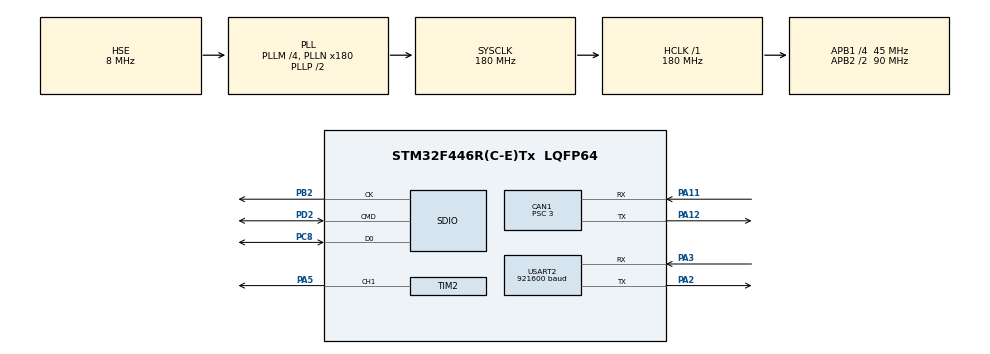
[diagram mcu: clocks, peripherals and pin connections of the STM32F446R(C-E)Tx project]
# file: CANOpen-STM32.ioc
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CAN1.BS1=CAN_BS1_12TQ
CAN1.BS2=CAN_BS2_3TQ
CAN1.CalculateTimeQuantum=66.66666666666666
CAN1.Prescaler=3
CAN1.SJW=CAN_SJW_2TQ
CAN1.TTCM=DISABLE
Dma.Request0=USART2_TX
Dma.USART2_TX.0.Direction=DMA_MEMORY_TO_PERIPH
Dma.USART2_TX.0.FIFOMode=DMA_FIFOMODE_DISABLE
Dma.USART2_TX.0.Instance=DMA1_Stream6
Dma.USART2_TX.0.MemDataAlignment=DMA_MDATAALIGN_BYTE
Dma.USART2_TX.0.MemInc=DMA_MINC_ENABLE
Dma.USART2_TX.0.Mode=DMA_NORMAL
Dma.USART2_TX.0.PeriphDataAlignment=DMA_PDATAALIGN_BYTE
Dma.USART2_TX.0.PeriphInc=DMA_PINC_DISABLE
Dma.USART2_TX.0.Priority=DMA_PRIORITY_LOW
FREERTOS.Tasks01=defaultTask,8,128,StartDefaultTask,Default,NULL,Static,defaultTaskBuffer,defaultTaskControlBlock;uartRxTask,9,256,StartUartRxTask,Default,NULL,Static,uartRxTaskBuffer,uartRxTaskControlBlock;canTxTask,24,256,StartCanTxTask,Default,NULL,Static,canTxTaskBuffer,canTxTaskControlBlock;canRxTask,24,256,StartCanRxTask,Default,NULL,Static,canRxTaskBuffer,canRxTaskControlBlock
Mcu.Family=STM32F4
Mcu.Name=STM32F446R(C-E)Tx
Mcu.Package=LQFP64
NVIC.DMA1_Stream6_IRQn=true\:5\:0\:false\:false\:true\:true\:false\:true
NVIC.PriorityGroup=NVIC_PRIORITYGROUP_4
NVIC.TIM2_IRQn=true\:5\:0\:false\:false\:true\:true\:true\:true
NVIC.TIM6_DAC_IRQn=true\:0\:0\:false\:false\:true\:false\:false\:true
NVIC.TIM7_IRQn=true\:5\:0\:false\:false\:true\:true\:true\:true
NVIC.TimeBase=TIM6_DAC_IRQn
NVIC.TimeBaseIP=TIM6
NVIC.USART2_IRQn=true\:5\:0\:false\:false\:true\:true\:true\:true
PA11.Mode=Master
PA11.Signal=CAN1_RX
PA12.Mode=Master
PA12.Signal=CAN1_TX
PA2.Mode=Asynchronous
PA2.Signal=USART2_TX
PA3.Mode=Asynchronous
PA3.Signal=USART2_RX
PA5.GPIO_Speed=GPIO_SPEED_FREQ_HIGH
PA5.Signal=S_TIM2_CH1_ETR
PB2.Mode=SD_1_bit
PB2.Signal=SDIO_CK
PC8.Mode=SD_1_bit
PC8.Signal=SDIO_D0
PD2.Mode=SD_1_bit
PD2.Signal=SDIO_CMD
PH0-OSC_IN.Mode=HSE-External-Oscillator
PH0-OSC_IN.Signal=RCC_OSC_IN
PH1-OSC_OUT.Mode=HSE-External-Oscillator
PH1-OSC_OUT.Signal=RCC_OSC_OUT
ProjectManager.HeapSize=0x200
ProjectManager.StackSize=0x400
ProjectManager.TargetToolchain=Makefile
RCC.AHBFreq_Value=180000000
RCC.APB1CLKDivider=RCC_HCLK_DIV4
RCC.APB1Freq_Value=45000000
RCC.APB1TimFreq_Value=90000000
RCC.APB2CLKDivider=RCC_HCLK_DIV2
RCC.APB2Freq_Value=90000000
RCC.APB2TimFreq_Value=180000000
RCC.CortexFreq_Value=180000000
RCC.HCLKFreq_Value=180000000
RCC.HSE_VALUE=8000000
RCC.PLLM=4
RCC.PLLN=180
RCC.PLLQ=8
RCC.PLLSourceVirtual=RCC_PLLSOURCE_HSE
RCC.SYSCLKFreq_VALUE=180000000
RCC.SYSCLKSource=RCC_SYSCLKSOURCE_PLLCLK
RCC.USBFreq_Value=45000000
RCC.VCOOutputFreq_Value=360000000
SH.S_TIM2_CH1_ETR.0=TIM2_CH1,PWM Generation1 CH1
TIM2.Channel-PWM\ Generation1\ CH1=TIM_CHANNEL_1
TIM2.Period=999
TIM2.Prescaler=89
TIM2.Pulse-PWM\ Generation1\ CH1=100
TIM7.AutoReloadPreload=TIM_AUTORELOAD_PRELOAD_DISABLE
TIM7.Period=9999
TIM7.Prescaler=8999
USART2.BaudRate=921600
USART2.VirtualMode=VM_ASYNC
VP_FREERTOS_VS_CMSIS_V2.Mode=CMSIS_V2
VP_SYS_VS_tim6.Mode=TIM6
VP_TIM2_VS_ClockSourceINT.Mode=Internal
VP_TIM7_VS_ClockSourceINT.Mode=Enable_Timer
board=custom

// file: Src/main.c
/* USER CODE BEGIN Header */
/**
  ******************************************************************************
  * @file           : main.c
  * @brief          : Main program body
  ******************************************************************************
  * @attention
  *
  * <h2><center>&copy; Copyright (c) 2020 STMicroelectronics.
  * All rights reserved.</center></h2>
  *
  * This software component is licensed by ST under Ultimate Liberty license
  * SLA0044, the "License"; You may not use this file except in compliance with
  * the License. You may obtain a copy of the License at:
  *                             www.st.com/SLA0044
  *
  ******************************************************************************
  */
/* USER CODE END Header */

#include "main.h"
#include "cmsis_os.h"
#include "can.h"
#include "dma.h"
#include "sdio.h"
#include "tim.h"
#include "usart.h"
#include "gpio.h"

void SystemClock_Config(void);
void MX_FREERTOS_Init(void);

int main(void)
{

  /* MCU Configuration--------------------------------------------------------*/

  /* Reset of all peripherals, Initializes the Flash interface and the Systick. */
  HAL_Init();

  /* Configure the system clock */
  SystemClock_Config();

  /* Initialize all configured peripherals */
  MX_GPIO_Init();
  MX_DMA_Init();
  MX_USART2_UART_Init();
  MX_TIM7_Init();
  MX_TIM2_Init();
  MX_CAN1_Init();
  MX_SDIO_SD_Init();
  /* USER CODE BEGIN 2 */
  USR_CAN1_Init();
  /* USER CODE END 2 */

  /* Call init function for freertos objects (in freertos.c) */
  MX_FREERTOS_Init();

  /* Start scheduler */
  osKernelStart();

  /* We should never get here as control is now taken by the scheduler */

  /* Infinite loop */
  while (1)
  {

  }
}

void SystemClock_Config(void)
{
  RCC_OscInitTypeDef RCC_OscInitStruct = {0};
  RCC_ClkInitTypeDef RCC_ClkInitStruct = {0};
  RCC_PeriphCLKInitTypeDef PeriphClkInitStruct = {0};

  /** Configure the main internal regulator output voltage
  */
  __HAL_RCC_PWR_CLK_ENABLE();
  __HAL_PWR_VOLTAGESCALING_CONFIG(PWR_REGULATOR_VOLTAGE_SCALE1);
  /** Initializes the CPU, AHB and APB busses clocks
  */
  RCC_OscInitStruct.OscillatorType = RCC_OSCILLATORTYPE_HSE;
  RCC_OscInitStruct.HSEState = RCC_HSE_ON;
  RCC_OscInitStruct.PLL.PLLState = RCC_PLL_ON;
  RCC_OscInitStruct.PLL.PLLSource = RCC_PLLSOURCE_HSE;
  RCC_OscInitStruct.PLL.PLLM = 4;
  RCC_OscInitStruct.PLL.PLLN = 180;
  RCC_OscInitStruct.PLL.PLLP = RCC_PLLP_DIV2;
  RCC_OscInitStruct.PLL.PLLQ = 8;
  RCC_OscInitStruct.PLL.PLLR = 2;
  if (HAL_RCC_OscConfig(&RCC_OscInitStruct) != HAL_OK)
  {
    Error_Handler();
  }
  /** Activate the Over-Drive mode
  */
  if (HAL_PWREx_EnableOverDrive() != HAL_OK)
  {
    Error_Handler();
  }
  /** Initializes the CPU, AHB and APB busses clocks
  */
  RCC_ClkInitStruct.ClockType = RCC_CLOCKTYPE_HCLK|RCC_CLOCKTYPE_SYSCLK
                              |RCC_CLOCKTYPE_PCLK1|RCC_CLOCKTYPE_PCLK2;
  RCC_ClkInitStruct.SYSCLKSource = RCC_SYSCLKSOURCE_PLLCLK;
  RCC_ClkInitStruct.AHBCLKDivider = RCC_SYSCLK_DIV1;
  RCC_ClkInitStruct.APB1CLKDivider = RCC_HCLK_DIV4;
  RCC_ClkInitStruct.APB2CLKDivider = RCC_HCLK_DIV2;

  if (HAL_RCC_ClockConfig(&RCC_ClkInitStruct, FLASH_LATENCY_5) != HAL_OK)
  {
    Error_Handler();
  }
  PeriphClkInitStruct.PeriphClockSelection = RCC_PERIPHCLK_SDIO|RCC_PERIPHCLK_CLK48;
  PeriphClkInitStruct.Clk48ClockSelection = RCC_CLK48CLKSOURCE_PLLQ;
  PeriphClkInitStruct.SdioClockSelection = RCC_SDIOCLKSOURCE_CLK48;
  if (HAL_RCCEx_PeriphCLKConfig(&PeriphClkInitStruct) != HAL_OK)
  {
    Error_Handler();
  }
}

void HAL_TIM_PeriodElapsedCallback(TIM_HandleTypeDef *htim)
{
  if (htim->Instance == TIM6) {
    HAL_IncTick();
  }
}

void Error_Handler(void)
{
}

/************************ (C) COPYRIGHT STMicroelectronics *****END OF FILE****/

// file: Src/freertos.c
/* USER CODE BEGIN Header */
/**
  ******************************************************************************
  * File Name          : freertos.c
  * Description        : Code for freertos applications
  ******************************************************************************
  * @attention
  *
  * <h2><center>&copy; Copyright (c) 2020 STMicroelectronics.
  * All rights reserved.</center></h2>
  *
  * This software component is licensed by ST under Ultimate Liberty license
  * SLA0044, the "License"; You may not use this file except in compliance with
  * the License. You may obtain a copy of the License at:
  *                             www.st.com/SLA0044
  *
  ******************************************************************************
  */
/* USER CODE END Header */

#include "FreeRTOS.h"
#include "task.h"
#include "main.h"
#include "cmsis_os.h"

/* USER CODE BEGIN Includes */
#include "usart.h"
#include "tim.h"
#include "can.h"
/* USER CODE END Includes */

typedef StaticTask_t osStaticThreadDef_t;
osThreadId_t defaultTaskHandle;
uint32_t defaultTaskBuffer[ 128 ];
osStaticThreadDef_t defaultTaskControlBlock;
osThreadId_t uartRxTaskHandle;
uint32_t uartRxTaskBuffer[ 256 ];
osStaticThreadDef_t uartRxTaskControlBlock;
osThreadId_t canTxTaskHandle;
uint32_t canTxTaskBuffer[ 256 ];
osStaticThreadDef_t canTxTaskControlBlock;
osThreadId_t canRxTaskHandle;
uint32_t canRxTaskBuffer[ 256 ];
osStaticThreadDef_t canRxTaskControlBlock;

void StartDefaultTask(void *argument);
void StartUartRxTask(void *argument);
void StartCanTxTask(void *argument);
void StartCanRxTask(void *argument);

void MX_FREERTOS_Init(void); /* (MISRA C 2004 rule 8.1) */

void MX_FREERTOS_Init(void) {
osKernelInitialize();

  /* Create the thread(s) */
  /* definition and creation of defaultTask */
  const osThreadAttr_t defaultTask_attributes = {
    .name = "defaultTask",
    .stack_mem = &defaultTaskBuffer[0],
    .stack_size = sizeof(defaultTaskBuffer),
    .cb_mem = &defaultTaskControlBlock,
    .cb_size = sizeof(defaultTaskControlBlock),
    .priority = (osPriority_t) osPriorityLow,
  };
  defaultTaskHandle = osThreadNew(StartDefaultTask, NULL, &defaultTask_attributes);

  /* definition and creation of uartRxTask */
  const osThreadAttr_t uartRxTask_attributes = {
    .name = "uartRxTask",
    .stack_mem = &uartRxTaskBuffer[0],
    .stack_size = sizeof(uartRxTaskBuffer),
    .cb_mem = &uartRxTaskControlBlock,
    .cb_size = sizeof(uartRxTaskControlBlock),
    .priority = (osPriority_t) osPriorityLow1,
  };
  uartRxTaskHandle = osThreadNew(StartUartRxTask, NULL, &uartRxTask_attributes);

  /* definition and creation of canTxTask */
  const osThreadAttr_t canTxTask_attributes = {
    .name = "canTxTask",
    .stack_mem = &canTxTaskBuffer[0],
    .stack_size = sizeof(canTxTaskBuffer),
    .cb_mem = &canTxTaskControlBlock,
    .cb_size = sizeof(canTxTaskControlBlock),
    .priority = (osPriority_t) osPriorityNormal,
  };
  canTxTaskHandle = osThreadNew(StartCanTxTask, NULL, &canTxTask_attributes);

  /* definition and creation of canRxTask */
  const osThreadAttr_t canRxTask_attributes = {
    .name = "canRxTask",
    .stack_mem = &canRxTaskBuffer[0],
    .stack_size = sizeof(canRxTaskBuffer),
    .cb_mem = &canRxTaskControlBlock,
    .cb_size = sizeof(canRxTaskControlBlock),
    .priority = (osPriority_t) osPriorityNormal,
  };
  canRxTaskHandle = osThreadNew(StartCanRxTask, NULL, &canRxTask_attributes);

}

void StartDefaultTask(void *argument)
{
  /* USER CODE BEGIN StartDefaultTask */

  /* Infinite loop */
  int counter = 0;
  HAL_TIM_Base_Start_IT(&htim7);
  HAL_TIM_PWM_Start_IT(&htim2, TIM_CHANNEL_1);

  for (;;)
  {
    uart_printf("FreeRTOS:loop counter=%d.\r\n",counter);
    counter++;
    osDelay(10000);
  }
  /* USER CODE END StartDefaultTask */
}

void StartUartRxTask(void *argument)
{
  for(;;)
  {
    osDelay(1);
  }
}

void StartCanTxTask(void *argument)
{
  /* USER CODE BEGIN StartCanTxTask */
  /* Infinite loop */
  for(;;)
  {
    osDelay(100);
    CANx_TxTest(&hcan1);
  }
  /* USER CODE END StartCanTxTask */
}

void StartCanRxTask(void *argument)
{
  /* USER CODE BEGIN StartCanRxTask */
  /* Infinite loop */
  for(;;)
  {
    osDelay(portMAX_DELAY);
  }
  /* USER CODE END StartCanRxTask */
}

/************************ (C) COPYRIGHT STMicroelectronics *****END OF FILE****/
